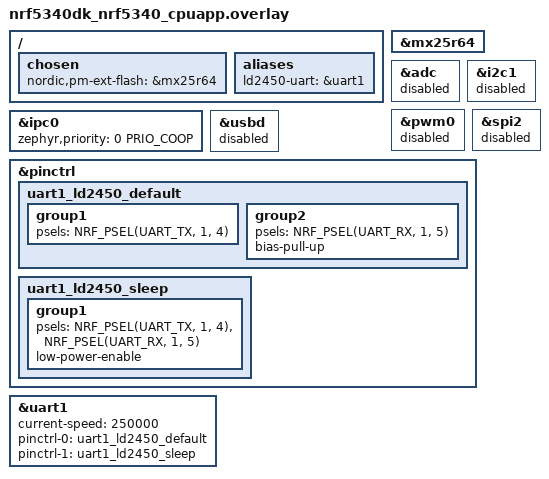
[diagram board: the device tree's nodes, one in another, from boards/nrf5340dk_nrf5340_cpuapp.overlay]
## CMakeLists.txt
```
#
# Copyright (c) 2025 Nordic Semiconductor ASA
#
# SPDX-License-Identifier: LicenseRef-Nordic-5-Clause
#

cmake_minimum_required(VERSION 3.20.0)

find_package(Zephyr HINTS $ENV{ZEPHYR_BASE})

project(matter-jamjari-occupancy)

# Enable GNU STD support.
include(${ZEPHYR_CONNECTEDHOMEIP_MODULE_DIR}/config/nrfconnect/app/enable-gnu-std.cmake)

# NORDIC SDK APP START

# Include all source files that are located in the Matter common directory.
include(${ZEPHYR_NRF_MODULE_DIR}/samples/matter/common/cmake/source_common.cmake)

# Include Data Model utils
include(${ZEPHYR_NRF_MODULE_DIR}/samples/matter/common/cmake/data_model.cmake)

include(${ZEPHYR_NRF_MODULE_DIR}/samples/matter/common/cmake/zap_helpers.cmake)
ncs_get_zap_parent_dir(ZAP_PARENT_DIR)

target_include_directories(app PRIVATE
  src
  ${ZAP_PARENT_DIR}
)

target_sources(app PRIVATE
  src/app_task.cpp
  src/bed_rules.cpp
  src/main.cpp
  src/ld2450.cpp
  src/ld2450_parser.cpp
  src/tracker.cpp
  src/zcl_callbacks.cpp
)
target_sources_ifdef(CONFIG_JAMJARI_DIRECT_UPLOAD app PRIVATE src/direct_upload.cpp)
# 재생 빌드: 재생 프레임(장면 시각·60GHz) 동기화 + 보드 추정
target_sources_ifdef(CONFIG_JAMJARI_RADAR_REPLAY app PRIVATE src/replay_frames.cpp)
target_sources_ifdef(CONFIG_JAMJARI_FUSION app PRIVATE src/fusion.cpp)

# 0x0431 은 SDK 에 서버 코드가 없다(초안 클러스터) — 속성 저장소만 쓴다
ncs_configure_data_model(EXTERNAL_CLUSTERS AMBIENT_CONTEXT_SENSING_CLUSTER)
# NORDIC SDK APP END
```

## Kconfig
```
#
# Copyright (c) 2025 Nordic Semiconductor
#
# SPDX-License-Identifier: LicenseRef-Nordic-5-Clause
#
mainmenu "Matter nRF Connect Jamjari Occupancy Sensor"

# 잠자리는 USB 전원이라 잠들 필요가 없다. 9/30 SED+LIT(ICD) 설정으로는 SmartThings 등록 중
# Thread 네트워크에 붙지 못하고 fail-safe 로 취소됐다. 전구 예제(등록 성공)와 같은 FTD·ICD 끔으로 둔다.
choice OPENTHREAD_NORDIC_LIBRARY_CONFIGURATION
	default OPENTHREAD_NORDIC_LIBRARY_FTD
endchoice

choice OPENTHREAD_DEVICE_TYPE
	default OPENTHREAD_FTD
endchoice

config CHIP_ENABLE_ICD_SUPPORT
	default n

menu "Jamjari direct upload"

config JAMJARI_DIRECT_UPLOAD
	bool "Board uploads events to the web server itself (Thread -> NAT64 -> HTTPS)"
	default n
	select MBEDTLS_TLS_LIBRARY
	# OT defconfig 가 TLS·클라이언트 기본값을 n 으로 둔다(조이너 등이 없을 때) → 여기서 켠다
	select MBEDTLS_SSL_TLS_C
	select MBEDTLS_SSL_CLI_C
	select PSA_WANT_KEY_TYPE_RSA_PUBLIC_KEY
	select PSA_WANT_RSA_KEY_SIZE_4096
	select PSA_WANT_ALG_RSA_PKCS1V15_SIGN
	select PSA_WANT_ALG_RSA_PSS
	# 뿌리 인증서가 SHA-384 로 서명됨(GTS R1). R4·X2(Cloudflare 쪽)는 P-384 키
	select PSA_WANT_ALG_SHA_384
	select PSA_WANT_ECC_SECP_R1_384
	help
	  E 계획: 보드가 맥 없이 SmartThings Station 의 NAT64 를 거쳐 jamjari.vercel.app 에
	  HTTPS 로 직접 올린다. Vercel 인증서가 RSA(루트 4096비트)라 RSA 검증을 켠다.
	  맥 수집기와 동시에 켜지 않는다(같은 사건이 두 번 저장됨).

endmenu

menu "Jamjari radar"

comment "지켜볼 구역(mm). 레이더 정면이 +y, 레이더에서 봐서 좌우가 x. 경계 포함."
comment "구역 밖 점은 사람으로 치지 않는다 (약 4m 거리의 유령 점을 거르려는 것)."

config JAMJARI_ZONE_XMIN
	int "Zone x min (mm)"
	range -6000 6000
	default -1500

config JAMJARI_ZONE_XMAX
	int "Zone x max (mm)"
	range -6000 6000
	default 1500

config JAMJARI_ZONE_YMIN
	int "Zone y min (mm)"
	range 0 8000
	default 0

config JAMJARI_ZONE_YMAX
	int "Zone y max (mm)"
	range 0 8000
	default 3000

config JAMJARI_RADAR_SUMMARY_LOG
	bool "Log a radar summary once per second"
	default y
	help
	  1초에 한 번 받은 프레임 수, 버린 바이트, 원시 타깃 수, 구역 안 사람(이름·x·y),
	  점유 상태를 INF 로 찍는다. 5초 넘게 프레임이 없으면 WRN 을 찍는다(이 경고는 끄지 않는다).

config JAMJARI_FRAME_LOG
	bool "Log one line per radar frame (for recording)"
	depends on LOG
	default y
	help
	  레이더 프레임 한 장마다 한 줄을 찍는다. 맥의 레이더_지도.py --source nrf 가 읽어서
	  지도로 그리고 녹화한다. 형식:
	    F <ms> <슬롯1> <슬롯2> <슬롯3> <구역 안 트랙 수> <occ>
	  슬롯은 원시 타깃 x,y,speed(mm, mm/s) 또는 빈 슬롯이면 -. 구역·트래커 전 값이다.
	  끝의 두 숫자는 보드가 그 프레임을 처리한 뒤의 판단(트랙 수, Occupancy 0/1).
	  한 줄 약 70바이트 × 초당 12장 ≈ 115200bps 의 8% 정도.

config JAMJARI_RADAR_REPLAY
	bool "Demo: read LD2450 frames from the Mac over VCOM instead of the radar"
	default n
	help
	  시연용(10/3, 센서 입력은 전부 더미로 가기로 함). 레이더 선 대신 디버거 USB 의 두 번째
	  통로(uart30, VCOM0, 115200bps)에서 LD2450 과 같은 30바이트 프레임을 받는다.
	  맥의 dummy/보드재생.py 가 더미 장면을 이 통로로 흘려 넣는다. 판단 코드는 그대로다.
	  ./build.sh --replay 가 replay/ 의 overlay·conf 로 켠다. 레이더용 빌드에는 쓰지 않는다.

config JAMJARI_FUSION
	bool "Board-side fusion: seat states + pet spots from replayed radar + 60GHz"
	depends on JAMJARI_RADAR_REPLAY
	default y
	help
	  보드 추정(10/5 N, 설계-보드추정.md). 맥 dummy/보드재생.py --g60 이 장면 시각을 붙여 보낸
	  레이더·60GHz 좌우 프레임으로 칸 상태(사람·반려동물로 추정·구분 안 됨·비어 있음)와
	  반려동물 머문 자리(10분 이상·최대 3개)를 보드에서 계산해 웹으로 보낸다(seat·spot 사건).
	  60GHz 는 가상 센서다.

comment "침대 칸 규칙 (설계-레이더2차.md). 침대 좌표가 모두 0 이면 끔 → 예전 규칙(구역 안 사람 있으면 1)."
comment "좌표계는 구역과 같다. 침대 사각형은 구역 안에 있어야 한다."

config JAMJARI_BED_XMIN
	int "Bed x min (mm)"
	range -6000 6000
	default 0

config JAMJARI_BED_XMAX
	int "Bed x max (mm)"
	range -6000 6000
	default 0

config JAMJARI_BED_YMIN
	int "Bed y min (mm)"
	range 0 8000
	default 0

config JAMJARI_BED_YMAX
	int "Bed y max (mm)"
	range 0 8000
	default 0

config JAMJARI_BED_SPLIT_X
	int "Bed left/right split x (mm)"
	range -6000 6000
	default 0
	help
	  x 가 이 값보다 작으면 왼쪽 칸(L), 아니면 오른쪽 칸(R). 레이더에서 본 기준.

config JAMJARI_BED_EDGE_MM
	int "Bed edge band width (mm)"
	range 0 2000
	default 300
	help
	  침대 좌우 두 변과 발치(ymin, 레이더 쪽) 안쪽 띠. 머리맡(ymax)은 띠 없음.
	  그 칸에서 온 점이 이 띠에서 사라지면 자리 뜸으로 본다.

config JAMJARI_LEAVE_DELAY_MS
	int "Delay before Occupancy=0 (ms)"
	range 1000 600000
	default 10000
	help
	  두 칸 다 꺼진 뒤(예전 규칙: 구역 안 사람이 없어진 뒤) Occupancy=0 까지.

config JAMJARI_HOLD_MAX_MIN
	int "Max hold without any point in bed (min)"
	range 1 1440
	default 720
	help
	  안전장치. 침대 안 점이 이만큼 하나도 없으면 두 칸 다 끈다.

config JAMJARI_MOVE_GAP_MS
	int "Movement gap that splits events (ms)"
	range 100 60000
	default 1000

config JAMJARI_MOVE_MIN_MS
	int "Minimum movement length (ms)"
	range 0 60000
	default 2000

config JAMJARI_FOLLOW_MS
	int "Follow window for L>R / R>L (ms)"
	range 0 600000
	default 30000
	help
	  한 칸 움직임이 끝나고 이 시간 안에 다른 칸이 시작하면 뒤쪽 줄에 「이어서 움직임」(L>R).
	  30000 = Pankhurst & Horne 1994 부부 연구의 30초 칸. 60000 = Hoffman 2020 개–사람 1분.
	  사람끼리 시차를 직접 잰 연구는 못 찾음(설계-레이더2차.md §3).

config JAMJARI_EVENT_LOG
	bool "Log JJ1,EV event lines"
	depends on LOG
	default y
	help
	  사건 줄 JJ1,EV,<seq>,<kind>,<start_ms>,<end_ms>,<size>,<x>,<y>,<count>,<flags>,<side> 를 찍는다.

endmenu

menu "Jamjari virtual temperature"

comment "시연용 가상 온도(endpoint 3). 범위는 ZAP 의 Min/MaxMeasuredValue(-10~40도)."

config JAMJARI_TEMP_START_CENTI
	int "Start temperature (0.01 C)"
	range -1000 4000
	default 2500

config JAMJARI_TEMP_STEP_CENTI
	int "Button step (0.01 C)"
	range 1 1000
	default 100

endmenu

source "$(ZEPHYR_CONNECTEDHOMEIP_MODULE_DIR)/config/nrfconnect/chip-module/Kconfig.features"
source "$(ZEPHYR_CONNECTEDHOMEIP_MODULE_DIR)/config/nrfconnect/chip-module/Kconfig.defaults"
source "$(ZEPHYR_NRF_MODULE_DIR)/samples/matter/common/src/Kconfig"
source "Kconfig.zephyr"
```

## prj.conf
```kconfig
#
# Copyright (c) 2025 Nordic Semiconductor ASA
#
# SPDX-License-Identifier: LicenseRef-Nordic-5-Clause
#

# Enable CHIP
CONFIG_CHIP=y
CONFIG_CHIP_PROJECT_CONFIG="src/chip_project_config.h"
CONFIG_CHIP_DEVICE_PRODUCT_NAME="Jamjari Occupancy Sensor"

# Configure ZAP file name
CONFIG_NCS_SAMPLE_MATTER_ZAP_FILE_PATH="${APPLICATION_CONFIG_DIR}/src/default_zap/occupancy_sensor.zap"

# 32768 == 0x8000 (example Product ID added temporaly,
# as there is no assigned PID on the following list:
# https://github.com/project-chip/connectedhomeip/blob/482e6fd03196a6de45465a90003947ef4b86e0b1/docs/examples/discussion/PID_allocation_for_example_apps.md)
CONFIG_CHIP_DEVICE_PRODUCT_ID=32768
CONFIG_STD_CPP17=y

# Enable Matter pairing automatically on application start.
CONFIG_CHIP_ENABLE_PAIRING_AUTOSTART=y

# Enable Matter extended announcement and increase duration to 1 hour.
CONFIG_CHIP_BLE_EXT_ADVERTISING=y
CONFIG_CHIP_BLE_ADVERTISING_DURATION=60

# Add support for LEDs and buttons on Nordic development kits
CONFIG_DK_LIBRARY=y

# Bluetooth Low Energy configuration
CONFIG_BT_DEVICE_NAME="Jamjari"
CONFIG_BT_DEVICE_NAME_MAX=18

# Suspend devices when the CPU goes into sleep
CONFIG_PM_DEVICE=y

# Other settings
CONFIG_THREAD_NAME=y
CONFIG_MPU_STACK_GUARD=y
CONFIG_RESET_ON_FATAL_ERROR=n
CONFIG_CHIP_LIB_SHELL=y
# E(보드 직접 전송) 1단계: 바깥 길 확인용 ot 셸 명령 (netdata·ping·dns)
CONFIG_OPENTHREAD_SHELL=y
# E 2단계①: OpenThread 를 소스로 빌드(미리 만든 FTD 라이브러리엔 TCP 가 없음). 기능 세트는 FTD 그대로
CONFIG_OPENTHREAD_SOURCES=y
CONFIG_OPENTHREAD_TCP_ENABLE=y
# TCP 를 켜면 OT 가 자기 TLS(ECJPAKE, 우리는 안 씀)까지 켜서 빌드가 깨짐 → 끔. 인터넷 TLS 는 앱에서 mbedTLS 로 따로
CONFIG_OPENTHREAD_CUSTOM_PARAMETERS="OPENTHREAD_CONFIG_TLS_ENABLE=0"
# E 2단계③: 보드가 HTTPS 로 직접 올리기 (Vercel 직통 · RSA 인증서 · SNI 필수)
CONFIG_JAMJARI_DIRECT_UPLOAD=y
# ECDHE-RSA 암호 묶음은 nrf_security 에서 아직 옛 RSA 설정(비공개 식별자)을 거쳐야 켜진다
CONFIG_MBEDTLS_DECLARE_PRIVATE_IDENTIFIERS=y
CONFIG_MBEDTLS_RSA_C=y
CONFIG_MBEDTLS_PKCS1_V15=y
CONFIG_MBEDTLS_PKCS1_V21=y
CONFIG_MBEDTLS_MPI_MAX_SIZE=512
CONFIG_MBEDTLS_KEY_EXCHANGE_ECDHE_RSA_ENABLED=y
CONFIG_MBEDTLS_SSL_SERVER_NAME_INDICATION=y
CONFIG_MBEDTLS_SSL_SRV_C=n
CONFIG_MBEDTLS_SSL_IN_CONTENT_LEN=16384
CONFIG_MBEDTLS_SSL_OUT_CONTENT_LEN=2048
CONFIG_MBEDTLS_HEAP_SIZE=49152

# Reduce application size
CONFIG_USE_SEGGER_RTT=n

# Enable Factory Data feature
CONFIG_CHIP_FACTORY_DATA=y
CONFIG_CHIP_FACTORY_DATA_BUILD=y

# 잠자리: HLK-LD2450 레이더 (uart1, 인터럽트 방식 수신)
CONFIG_SERIAL=y
CONFIG_UART_INTERRUPT_DRIVEN=y
```

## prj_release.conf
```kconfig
#
# Copyright (c) 2025 Nordic Semiconductor ASA
#
# SPDX-License-Identifier: LicenseRef-Nordic-5-Clause
#

# Enable CHIP
CONFIG_CHIP=y
CONFIG_CHIP_PROJECT_CONFIG="src/chip_project_config.h"
CONFIG_CHIP_DEVICE_PRODUCT_NAME="Jamjari Occupancy Sensor"

# Configure ZAP file name
CONFIG_NCS_SAMPLE_MATTER_ZAP_FILE_PATH="${APPLICATION_CONFIG_DIR}/src/default_zap/occupancy_sensor.zap"

# 32768 == 0x8000 (example Product ID added temporaly,
# as there is no assigned PID on the following list:
# https://github.com/project-chip/connectedhomeip/blob/482e6fd03196a6de45465a90003947ef4b86e0b1/docs/examples/discussion/PID_allocation_for_example_apps.md)
CONFIG_CHIP_DEVICE_PRODUCT_ID=32768
CONFIG_STD_CPP17=y

# Enable Matter pairing automatically on application start.
CONFIG_CHIP_ENABLE_PAIRING_AUTOSTART=y

# Enable Matter extended announcement and increase duration to 1 hour.
CONFIG_CHIP_BLE_EXT_ADVERTISING=y
CONFIG_CHIP_BLE_ADVERTISING_DURATION=60

# Add support for LEDs and buttons on Nordic development kits
CONFIG_DK_LIBRARY=y

# Try to disable unused RAM blocks to reduce power consumption
CONFIG_RAM_POWER_DOWN_LIBRARY=y

# Bluetooth Low Energy configuration
CONFIG_BT_DEVICE_NAME="Jamjari"
CONFIG_BT_DEVICE_NAME_MAX=18

# Suspend devices when the CPU goes into sleep
CONFIG_PM_DEVICE=y

# Enable system reset on fatal error
CONFIG_RESET_ON_FATAL_ERROR=y

# Disable all debug features
CONFIG_USE_SEGGER_RTT=n
CONFIG_SHELL=n
CONFIG_OPENTHREAD_SHELL=n
CONFIG_CONSOLE=n
CONFIG_UART_CONSOLE=n
# 콘솔은 끄되 LD2450 용 uart1 은 필요하다
CONFIG_SERIAL=y
CONFIG_UART_INTERRUPT_DRIVEN=y
CONFIG_LOG=n
CONFIG_LOG_MODE_MINIMAL=n
CONFIG_ASSERT_VERBOSE=n
CONFIG_ASSERT_NO_FILE_INFO=y
CONFIG_PRINTK=n
CONFIG_PRINTK_SYNC=n
CONFIG_THREAD_NAME=n
CONFIG_BOOT_BANNER=n

# Enable Factory Data feature
CONFIG_CHIP_FACTORY_DATA=y
CONFIG_CHIP_FACTORY_DATA_BUILD=y

# Enable Watchdog
CONFIG_NCS_SAMPLE_MATTER_WATCHDOG=y

# Enable LTO to decrease the flash usage.
CONFIG_LTO=y
CONFIG_ISR_TABLES_LOCAL_DECLARATION=y
```

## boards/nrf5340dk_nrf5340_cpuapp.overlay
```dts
/*
 * Copyright (c) 2025 Nordic Semiconductor ASA
 *
 * SPDX-License-Identifier: LicenseRef-Nordic-5-Clause
 */

#include <samples/matter/nrf5340_cpuapp_partitions.dtsi>
#include <zephyr/dt-bindings/ipc_service/static_vrings.h>

/* Set IPC thread priority to the highest value to not collide with other threads. */
&ipc0 {
	zephyr,priority = <0 PRIO_COOP>;
};

/ {
	chosen {
		nordic,pm-ext-flash = &mx25r64;
	};
};

&mx25r64 {
	status = "okay";
};

/* Disable unused peripherals to reduce power consumption */
&adc {
	status = "disabled";
};

&i2c1 {
	status = "disabled";
};

&pwm0 {
	status = "disabled";
};

&spi2 {
	status = "disabled";
};

&usbd {
	status = "disabled";
};

/*
 * 잠자리: HLK-LD2450 레이더용 UART.
 * uart1 의 기본 핀(P1.00/P1.01)은 네트워크 코어 UART 로 넘겨지고(gpio_fwd)
 * DK 디버거 VCOM 에도 물려 있어서 쓰지 않는다. 비어 있는 Arduino D2/D3 로 옮긴다.
 *   TX  P1.04 (Arduino D2) -> LD2450 RX
 *   RX  P1.05 (Arduino D3) <- LD2450 TX
 * UARTE1 은 TWIM1(i2c1) 과 같은 주변장치를 공유한다. i2c1 은 위에서 disabled.
 * current-speed 는 드라이버가 허용하는 250000 으로 두고, 실제 256000 설정은
 * src/ld2450.cpp 에서 BAUDRATE 레지스터에 직접 쓴다.
 */
/ {
	aliases {
		ld2450-uart = &uart1;
	};
};

&pinctrl {
	uart1_ld2450_default: uart1_ld2450_default {
		group1 {
			psels = <NRF_PSEL(UART_TX, 1, 4)>;
		};
		group2 {
			psels = <NRF_PSEL(UART_RX, 1, 5)>;
			bias-pull-up;
		};
	};

	uart1_ld2450_sleep: uart1_ld2450_sleep {
		group1 {
			psels = <NRF_PSEL(UART_TX, 1, 4)>,
				<NRF_PSEL(UART_RX, 1, 5)>;
			low-power-enable;
		};
	};
};

&uart1 {
	status = "okay";
	current-speed = <250000>;
	pinctrl-0 = <&uart1_ld2450_default>;
	pinctrl-1 = <&uart1_ld2450_sleep>;
	pinctrl-names = "default", "sleep";
};
```

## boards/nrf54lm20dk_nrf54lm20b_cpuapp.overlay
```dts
/*
 * Copyright (c) 2026 Nordic Semiconductor ASA
 *
 * SPDX-License-Identifier: LicenseRef-Nordic-5-Clause
 */

#include <samples/matter/nrf54lm20_cpuapp_partitions.dtsi>

/ {
	aliases {
		/* Use watchdog wdt31 as the application watchdog */
		watchdog0 = &wdt31;
	};

	chosen {
		nordic,pm-ext-flash = &mx25r64;
	};
};

&mx25r64 {
	status = "okay";
};

&wdt31 {
	status = "okay";
};

/*
 * 잠자리: HLK-LD2450 레이더용 UART (nRF54LM20 DK).
 * uart20 은 콘솔(디버거 VCOM)이라 쓰지 않고, 비어 있는 uart21 을 쓴다.
 * uart21 은 16MHz 주변장치 도메인이라 src/ld2450.cpp 의 256000 BAUDRATE 레지스터 값
 * (16MHz 기준 공식)이 그대로 맞다. 핀은 확장 헤더의 P1 포트에서 고른다
 * (주변장치 도메인 UARTE 는 P1 핀을 쓴다).
 *   TX  P1.04 -> LD2450 RX
 *   RX  P1.05 <- LD2450 TX
 * 🔴 DK 의 VDD(GPIO 전압) 기본값이 1.8V 일 수 있다. 레이더 TX 는 3.3V 라서
 *    Board Configurator 로 VDD 를 3.3V 로 올린 뒤에 선을 꽂는다.
 */
/ {
	aliases {
		ld2450-uart = &uart21;
	};
};

&pinctrl {
	uart21_ld2450_default: uart21_ld2450_default {
		group1 {
			psels = <NRF_PSEL(UART_TX, 1, 4)>;
		};
		group2 {
			psels = <NRF_PSEL(UART_RX, 1, 5)>;
			bias-pull-up;
		};
	};

	uart21_ld2450_sleep: uart21_ld2450_sleep {
		group1 {
			psels = <NRF_PSEL(UART_TX, 1, 4)>,
				<NRF_PSEL(UART_RX, 1, 5)>;
			low-power-enable;
		};
	};
};

&uart21 {
	status = "okay";
	current-speed = <250000>;
	pinctrl-0 = <&uart21_ld2450_default>;
	pinctrl-1 = <&uart21_ld2450_sleep>;
	pinctrl-names = "default", "sleep";
};
```

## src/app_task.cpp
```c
/*
 * Copyright (c) 2025 Nordic Semiconductor ASA
 *
 * SPDX-License-Identifier: LicenseRef-Nordic-5-Clause
 */

#include "app_task.h"
#include "bed_rules.h"
#ifdef CONFIG_JAMJARI_DIRECT_UPLOAD
#include "direct_upload.h"
#endif
#ifdef CONFIG_JAMJARI_FUSION
#include "fusion.h"
#include "ld2450_parser.h"
#include "replay_frames.h"
#endif
#include "ld2450.h"
#include "tracker.h"

#include "app/matter_init.h"
#include "app/task_executor.h"
#include "board/board.h"
#include "clusters/identify.h"

#include "lib/core/CHIPError.h"
#include <app-common/zap-generated/attribute-type.h>
#include <app-common/zap-generated/attributes/Accessors.h>
#include <app/clusters/occupancy-sensor-server/occupancy-sensor-server.h>
#include <app/util/attribute-table.h>

#include <dk_buttons_and_leds.h>
#include <zephyr/logging/log.h>
#include <zephyr/shell/shell.h>

#include <cstdio>
#include <cstdlib>
#include <cstring>

LOG_MODULE_DECLARE(app, CONFIG_CHIP_APP_LOG_LEVEL);

using namespace ::chip;
using namespace ::chip::app;
using namespace ::chip::DeviceLayer;

namespace
{
constexpr chip::EndpointId kOccupancySensorEndpointId = 1;
/* 0x0431 Ambient Context Sensing (Matter 다음 규격 초안, ZAP 정의는 src/default_zap/zcl/) */
constexpr chip::ClusterId kAmbientContextSensingClusterId = 0x0431;
constexpr chip::AttributeId kHumanActivityDetectedAttributeId = 0x0000;
/*
 * 시연용 가상 조도 (Light Sensor). 5 lux 고정(ZAP 기본값 6991 = 10000*log10(5)+1).
 * SmartThings Matter Sensor 드라이버에 「동작+온도」 모양이 없고 「동작+조도+온도」는 있어서 넣었다.
 * 예전 ep2 「감지 멈춤」 On/Off 스위치는 SmartThings 가 기기 전체를 플러그로 잡아 동작 감지를 가려서 뺐다 → BTN2 만 남음.
 */
constexpr chip::EndpointId kLightSensorEndpointId = 2;
/* 시연용 가상 온도 (Temperature Sensor). 값은 버튼·셸(temp)로만 바뀐다. */
constexpr chip::EndpointId kTemperatureSensorEndpointId = 3;

atomic_t sOccupied = ATOMIC_INIT(0);
/* 멈춤 요청(1=멈춤). Matter 스레드가 쓰고, 리더 스레드가 ApplyPauseState 로 반영한다. */
atomic_t sPaused = ATOMIC_INIT(0);

/* Identify 가 끝나면 LED2 를 끄지 말고 지금 Occupancy 로 되돌린다 */
void RestoreOccupancyLed()
{
	Nrf::PostTask([] { Nrf::GetBoard().GetLED(Nrf::DeviceLeds::LED2).Set(atomic_get(&sOccupied) != 0); });
}

Nrf::Matter::IdentifyCluster sIdentifyCluster(kOccupancySensorEndpointId, true, RestoreOccupancyLed);
Nrf::Matter::IdentifyCluster sLightIdentifyCluster(kLightSensorEndpointId, true, RestoreOccupancyLed);
Nrf::Matter::IdentifyCluster sTempIdentifyCluster(kTemperatureSensorEndpointId, true, RestoreOccupancyLed);

/* FeatureMap = Radar. 이 클러스터의 FeatureMap/ClusterRevision 은 이 인스턴스가 응답한다. */
Clusters::OccupancySensing::Instance
	sOccupancyInstance(BitMask<Clusters::OccupancySensing::Feature>(Clusters::OccupancySensing::Feature::kRadar));

/* 지켜볼 구역(mm). Kconfig CONFIG_JAMJARI_ZONE_* 로 바꾼다(README 「구역 조정」). */
constexpr Tracker::Zone kZone = { CONFIG_JAMJARI_ZONE_XMIN, CONFIG_JAMJARI_ZONE_XMAX, CONFIG_JAMJARI_ZONE_YMIN,
				  CONFIG_JAMJARI_ZONE_YMAX };
constexpr int64_t kRadarSilentMs = 5000;

/* 침대 칸 규칙(bed_rules.h). 침대 좌표가 모두 0 이면 예전 규칙. Kconfig CONFIG_JAMJARI_BED_* 등 */
constexpr BedRules::Config kBedConfig = {
	{ CONFIG_JAMJARI_BED_XMIN, CONFIG_JAMJARI_BED_XMAX, CONFIG_JAMJARI_BED_YMIN, CONFIG_JAMJARI_BED_YMAX,
	  CONFIG_JAMJARI_BED_SPLIT_X, CONFIG_JAMJARI_BED_EDGE_MM },
	CONFIG_JAMJARI_LEAVE_DELAY_MS,
	static_cast<int64_t>(CONFIG_JAMJARI_HOLD_MAX_MIN) * 60 * 1000,
	CONFIG_JAMJARI_MOVE_GAP_MS,
	CONFIG_JAMJARI_MOVE_MIN_MS,
	CONFIG_JAMJARI_FOLLOW_MS,
};

/* 침대 좌표 오설정은 빌드에서 막는다(미설정 = 모두 0 이면 검사 안 함) */
constexpr bool kBedSet = CONFIG_JAMJARI_BED_XMIN != 0 || CONFIG_JAMJARI_BED_XMAX != 0 ||
			 CONFIG_JAMJARI_BED_YMIN != 0 || CONFIG_JAMJARI_BED_YMAX != 0;
static_assert(!kBedSet || (CONFIG_JAMJARI_BED_XMIN < CONFIG_JAMJARI_BED_XMAX &&
			   CONFIG_JAMJARI_BED_YMIN < CONFIG_JAMJARI_BED_YMAX),
	      "침대 좌표: XMIN<XMAX, YMIN<YMAX 이어야 한다 (네 값을 다 넣었나?)");
static_assert(!kBedSet || (CONFIG_JAMJARI_BED_XMIN <= CONFIG_JAMJARI_BED_SPLIT_X &&
			   CONFIG_JAMJARI_BED_SPLIT_X <= CONFIG_JAMJARI_BED_XMAX),
	      "침대 좌표: SPLIT_X 는 XMIN..XMAX 안이어야 한다");
static_assert(!kBedSet || (2 * CONFIG_JAMJARI_BED_EDGE_MM < CONFIG_JAMJARI_BED_XMAX - CONFIG_JAMJARI_BED_XMIN &&
			   CONFIG_JAMJARI_BED_EDGE_MM < CONFIG_JAMJARI_BED_YMAX - CONFIG_JAMJARI_BED_YMIN),
	      "침대 좌표: 가장자리 띠가 침대보다 넓다 (EDGE_MM 줄이기)");
static_assert(!kBedSet || (CONFIG_JAMJARI_ZONE_XMIN <= CONFIG_JAMJARI_BED_XMIN &&
			   CONFIG_JAMJARI_BED_XMAX <= CONFIG_JAMJARI_ZONE_XMAX &&
			   CONFIG_JAMJARI_ZONE_YMIN <= CONFIG_JAMJARI_BED_YMIN &&
			   CONFIG_JAMJARI_BED_YMAX <= CONFIG_JAMJARI_ZONE_YMAX),
	      "침대 좌표: 침대는 구역(JAMJARI_ZONE_*) 안에 있어야 한다 (밖은 트래커가 버린다)");

/* 아래 셋은 LD2450 리더 스레드에서만 만진다(프레임 핸들러와 1초 틱이 같은 스레드) */
Tracker::State sTracker;
BedRules::State sBed;
uint8_t sLastRawCount;
int64_t sLastSilentWarnMs;
bool sAppliedPaused; /* 리더 스레드가 마지막으로 반영한 멈춤 상태 */

void ReportOccupancy(bool occupied)
{
	/* 상태가 바뀔 때만 Matter 스레드에 넘긴다 */
	if (atomic_set(&sOccupied, occupied ? 1 : 0) == (occupied ? 1 : 0)) {
		return;
	}
	LOG_INF("Occupancy -> %d", occupied);
	/*
	 * 레이더 리더 스레드와 시스템 워크큐(SetSensing — BTN2 콜백) 둘 다 부른다. 두 스레드가 거의 같이 부르면 일이 두 개
	 * 쌓이는데, 일은 넘길 때 값이 아니라 실행할 때 sOccupied 를 읽는다 — 마지막 일이 늘 최신 값을 쓰므로
	 * 속성과 LED2 가 sOccupied 와 어긋난 채 남지 않는다. LED 는 앱 스레드에서 바꾼다.
	 */
	DeviceLayer::PlatformMgr().ScheduleWork(
		[](intptr_t) {
			bool now = atomic_get(&sOccupied) != 0;
			Nrf::PostTask([now] { Nrf::GetBoard().GetLED(Nrf::DeviceLeds::LED2).Set(now); });
			BitMask<Clusters::OccupancySensing::OccupancyBitmap> value;
			if (now) {
				value.Set(Clusters::OccupancySensing::OccupancyBitmap::kOccupied);
			}
			Protocols::InteractionModel::Status status =
				Clusters::OccupancySensing::Attributes::Occupancy::Set(kOccupancySensorEndpointId,
										       value);
			if (status != Protocols::InteractionModel::Status::Success) {
				LOG_ERR("Updating occupancy failed %x", to_underlying(status));
			}
			/*
			 * 0x0431 Ambient Context Sensing(초안) HumanActivityDetected 도 같은 값으로. SDK 에 이 클러스터의
			 * Accessors 가 없어서 속성 저장소에 바로 쓴다(Matter 스레드라 잠금 안). HumanActivityType 은 Other(0) 고정.
			 */
			uint8_t detected = now ? 1 : 0;
			status = emberAfWriteAttribute(kOccupancySensorEndpointId, kAmbientContextSensingClusterId,
						       kHumanActivityDetectedAttributeId, &detected,
						       ZCL_BOOLEAN_ATTRIBUTE_TYPE);
			if (status != Protocols::InteractionModel::Status::Success) {
				LOG_ERR("Updating 0x0431 HumanActivityDetected failed %x", to_underlying(status));
			}
		},
		0);
}

/*
 * 리더 스레드에서 프레임·틱마다 맨 먼저 부른다. 반환값 = 지금 멈춤인가.
 * 멈춤/재개가 바뀌는 순간 트래커와 침대 칸 상태를 새로 시작한다 — 열려 있던 사건(움직임 묶음·away)은
 * 버린다. 사건 번호(seq)만 이어 간다(맥 쪽이 번호로 줄을 맞춘다).
 */
bool ApplyPauseState()
{
	bool paused = atomic_get(&sPaused) != 0;
	if (paused == sAppliedPaused) {
		return paused;
	}
	sAppliedPaused = paused;
	uint32_t seq = sBed.seq;
	sTracker = {};
	sBed = {};
	sBed.seq = seq;
	if (paused) {
		/* 멈춤 중엔 비어 있음으로 둔다(SetSensing 도 내리지만, 그 사이 프레임이 올렸을 수 있다) */
		ReportOccupancy(false);
	}
	return paused;
}

/* 사건 줄 출력 (Kconfig JAMJARI_EVENT_LOG). 맥은 JJ1, 이후만 읽는다.
 * 직접 전송(JAMJARI_DIRECT_UPLOAD)이면 같은 사건을 보낼 줄에도 넣는다. */
void LogEvents(const BedRules::EventBuf &out)
{
#ifdef CONFIG_JAMJARI_DIRECT_UPLOAD
	for (size_t i = 0; i < out.n; i++) {
		DirectUpload::QueueEvent(out.ev[i]);
	}
#endif
#ifdef CONFIG_JAMJARI_EVENT_LOG
	for (size_t i = 0; i < out.n; i++) {
		char line[96];
		BedRules::FormatEvent(out.ev[i], line, sizeof(line));
		LOG_INF("%s", line);
	}
	if (out.overflow) {
		LOG_WRN("사건 %u개 못 냄 (EventBuf 가득)", static_cast<unsigned>(out.overflow));
	}
#else
	ARG_UNUSED(out);
#endif
}

/* 프레임 한 줄 출력: F <ms> <슬롯×3> <트랙 수> <occ> (Kconfig JAMJARI_FRAME_LOG, 맥의 레이더_지도.py --source nrf 가 읽는다) */
void LogFrame(const Ld2450::Target (&targets)[Ld2450::kTargetSlots])
{
#ifdef CONFIG_JAMJARI_FRAME_LOG
	/* 슬롯 하나 최대 " -32767,-32767,-327670" 22자 */
	char slots[Ld2450::kTargetSlots * 24] = "";
	size_t len = 0;
	for (size_t i = 0; i < Ld2450::kTargetSlots; i++) {
		const Ld2450::Target &t = targets[i];
		int n = t.present ? snprintf(slots + len, sizeof(slots) - len, " %d,%d,%d", t.x, t.y,
					     static_cast<int>(t.speed))
				  : snprintf(slots + len, sizeof(slots) - len, " -");
		if (n < 0 || static_cast<size_t>(n) >= sizeof(slots) - len) {
			break;
		}
		len += static_cast<size_t>(n);
	}
	LOG_INF("F %u%s %u %d", static_cast<unsigned>(k_uptime_get_32()), slots,
		static_cast<unsigned>(sTracker.count), static_cast<int>(atomic_get(&sOccupied)));
#else
	ARG_UNUSED(targets);
#endif
}

/*
 * LD2450 리더 스레드에서 프레임마다 불린다.
 * 구역 필터·트래커 → 침대 칸 규칙(bed_rules) 순서. 원시 타깃이 아니라 트래커 결과로 판정한다 —
 * 구역 밖 유령 점이 Occupancy 를 붙잡지 않게. 침대 좌표 미설정이면 예전 규칙(구역 안 사람 1명 이상 → 1,
 * 마지막으로 있던 때부터 10초 → 0). (호스트 테스트: test/run_tracker.cpp 는 예전 규칙을 occupancy.h 로 본다)
 */
void OnRadarFrame(const Ld2450::Target (&targets)[Ld2450::kTargetSlots], uint8_t liveCount)
{
	sLastRawCount = liveCount;
	if (ApplyPauseState()) {
		return;
	}
	int64_t nowMs = k_uptime_get();
	Tracker::Update(sTracker, targets, kZone, nowMs);
	BedRules::EventBuf out;
	bool occupied = BedRules::Update(sBed, kBedConfig, sTracker, nowMs, out);
	/* 판단 도중 멈춤이 들어왔으면 결과를 버린다(JJ1,PAUSE,1 뒤에 occ 1·JJ1,EV 가 나가지 않게) */
	if (atomic_get(&sPaused)) {
		return;
	}
	ReportOccupancy(occupied);
	LogEvents(out);
	LogFrame(targets);
}

#ifdef CONFIG_JAMJARI_FUSION
/*
 * 보드 추정(fusion, 설계-보드추정.md). 맥이 장면 시각을 붙여 보낸 프레임으로 칸 상태·머문 자리를 계산한다.
 * 리더 스레드에서만 불린다(sFusion 은 이 스레드 전용). 결과는 로그 한 줄 + 웹 전송 줄(seat·spot).
 *   JJ1,SEAT,<장면 초>,<L|R>,<0 비어 있음|1 사람|2 반려동물로 추정|3 구분 안 됨>,<단서 0~3: A=1 B=2>
 *   JJ1,SPOT,<순위>,<from 초>,<to 초>,<x>,<y>,<머문 초>
 */
Fusion::Engine sFusion;
Fusion::SideOut sSeatPrev[2];
bool sSeatSent;
uint32_t sFusionSeq; /* 웹 src_id 가 bed_rules 사건과 안 겹치게 위 비트를 켠 번호를 쓴다 */
int32_t sSec0 = -1, sSecLast; /* 장면 초 ↔ 보드 시계: 첫 초와 마지막 초에 받은 보드 시각으로 선형 대응 */
int64_t sUp0, sUpLast;

void FusionReset()
{
	Fusion::Init(sFusion);
	sSeatSent = false;
	sSec0 = -1;
}

int64_t SceneToUptime(int32_t sec)
{
	if (sSec0 < 0 || sSecLast <= sSec0) {
		return sUp0;
	}
	return sUp0 + (static_cast<int64_t>(sec) - sSec0) * (sUpLast - sUp0) / (sSecLast - sSec0);
}

void QueueFusionEvent(BedRules::Kind kind, int64_t startMs, int64_t endMs, uint8_t size, int32_t x, int32_t y,
		      uint8_t count)
{
#ifdef CONFIG_JAMJARI_DIRECT_UPLOAD
	BedRules::Event ev = {};
	ev.seq = 0x80000000u | ++sFusionSeq;
	ev.kind = kind;
	ev.startMs = startMs;
	ev.endMs = endMs;
	ev.size = size;
	ev.x = x;
	ev.y = y;
	ev.count = count;
	DirectUpload::QueueEvent(ev);
#endif
}

Fusion::G60 G60Side(const uint8_t *p)
{
	return { p[0], static_cast<int16_t>(p[1] == 0xFF ? -1 : p[1]), static_cast<int16_t>(p[2] == 0xFF ? -1 : p[2]), p[3] };
}

void OnReplayFrame(const uint8_t *frame)
{
	using ReplayFrames::Type;
	Type type = static_cast<Type>(frame[2]);
	if (type == Type::kStart) {
		LOG_INF("fusion: 재생 시작 → 새로 시작");
		FusionReset();
		return;
	}
	/* 감지 멈춤 중엔 추정도 멈춘다. 장면 끝은 리셋만 한다(멈춘 동안의 결과는 안 낸다) */
	if (atomic_get(&sPaused)) {
		if (type == Type::kEnd) {
			LOG_INF("fusion: 감지 멈춤 중 장면 끝 → 머문 자리 안 내고 새로 시작");
			FusionReset();
		}
		return;
	}
	switch (type) {
	case Type::kRadar: {
		Ld2450::Target targets[Ld2450::kTargetSlots];
		Ld2450::ParseFrame(frame + 4, targets);
		Fusion::Point pts[Ld2450::kTargetSlots];
		size_t n = 0;
		for (const auto &t : targets) {
			if (t.present) {
				pts[n++] = { t.x, t.y };
			}
		}
		Fusion::Radar(sFusion, ReplayFrames::U32(frame + 4) / 1000.0, pts, n);
		break;
	}
	case Type::kG60: {
		int32_t sec = static_cast<int32_t>(ReplayFrames::U32(frame + 4));
		/* 장면 초는 1씩 이어진다. 안 이어지면(시작 프레임을 놓친 다른 재생) 새로 시작 */
		if (sSec0 >= 0 && sec != sFusion.judged) {
			LOG_INF("fusion: 장면 초가 안 이어짐(%d초, 기대 %d초) → 새로 시작", sec, sFusion.judged);
			FusionReset();
		}
		int64_t now = k_uptime_get();
		if (sSec0 < 0) {
			sSec0 = sec;
			sUp0 = now;
		}
		sSecLast = sec;
		sUpLast = now;
		Fusion::SecondOut o = Fusion::Judge(sFusion, sec, G60Side(frame + 8), G60Side(frame + 12));
		for (int side = 0; side < 2; side++) {
			const Fusion::SideOut &s = o.side[side];
			if (sSeatSent && s.state == sSeatPrev[side].state && s.clues == sSeatPrev[side].clues) {
				continue;
			}
			sSeatPrev[side] = s;
			LOG_INF("JJ1,SEAT,%d,%c,%u,%u", sec, side ? 'R' : 'L', static_cast<unsigned>(s.state),
				static_cast<unsigned>(s.clues));
			/* 칸은 x 부호로(L 음수·R 양수, 칸 가운데), 상태는 size, 단서는 count */
			QueueFusionEvent(BedRules::Kind::kSeat, now, now, static_cast<uint8_t>(s.state), side ? 400 : -400,
					 1300, s.clues);
		}
		sSeatSent = true;
		break;
	}
	case Type::kEnd: {
		Fusion::Spot spots[Fusion::kMaxSpots];
		size_t n = Fusion::End(sFusion, spots);
		LOG_INF("fusion: 장면 끝 %d초, 머문 자리 %u개 (넘침 트랙 %u/%u 자리 %u)", sFusion.judged,
			static_cast<unsigned>(n), static_cast<unsigned>(sFusion.m.overflow),
			static_cast<unsigned>(sFusion.n.overflow), static_cast<unsigned>(sFusion.s.overflow));
		for (size_t i = 0; i < n; i++) {
			const Fusion::Spot &sp = spots[i];
			LOG_INF("JJ1,SPOT,%u,%d,%d,%d,%d,%d", static_cast<unsigned>(i + 1), sp.from, sp.to, sp.x, sp.y,
				sp.still);
			int32_t minutes = sp.still / 60;
			QueueFusionEvent(BedRules::Kind::kSpot, SceneToUptime(sp.from), SceneToUptime(sp.to),
					 static_cast<uint8_t>(i + 1), sp.x, sp.y, static_cast<uint8_t>(minutes > 255 ? 255 : minutes));
		}
		FusionReset();
		break;
	}
	default:
		break;
	}
}
#endif

/* LD2450 리더 스레드에서 1초마다 불린다: 레이더 상태 요약 + 신호 끊김 경고 */
void OnRadarTick(const Ld2450::Stats &stats, int64_t nowMs)
{
	bool paused = ApplyPauseState();
	if (!paused) {
		/* 프레임이 끊겨도 시간으로 내리는 판단(occ 0·움직임 닫기)은 여기서 */
		BedRules::EventBuf out;
		bool occupied = BedRules::Tick(sBed, kBedConfig, nowMs, out);
		/* 판단 도중 멈춤이 들어왔으면 결과를 버린다(OnRadarFrame 과 같은 이유) */
		if (!atomic_get(&sPaused)) {
			ReportOccupancy(occupied);
			LogEvents(out);
		}
	}
#ifdef CONFIG_JAMJARI_DIRECT_UPLOAD
	/* 레이더 상태 숫자는 멈춤 중에도 갱신(보낼 묶음의 상태 칸) */
	DirectUpload::NoteRadarStats(stats);
#endif

	/* 레이더 끊김 경고는 멈춤 중에도 낸다 */
	int64_t silentMs = nowMs - (stats.lastFrameMs < 0 ? 0 : stats.lastFrameMs);
	if (silentMs > kRadarSilentMs && nowMs - sLastSilentWarnMs >= kRadarSilentMs) {
		sLastSilentWarnMs = nowMs;
		LOG_WRN("레이더 신호 없음 — 배선/5V 확인 (%lld초째 프레임 없음, 누적 %u프레임)",
			static_cast<long long>(silentMs / 1000), stats.frames);
	}

#ifdef CONFIG_JAMJARI_RADAR_SUMMARY_LOG
	static Ld2450::Stats sPrev = { 0, 0, 0, -1 };
	if (paused) {
		sPrev = stats; /* 재개 첫 줄의 fps 가 멈춤 동안 누적값이 되지 않게 */
		return;
	}
	char people[Tracker::kMaxTracks * 24] = "";
	size_t len = 0;
	for (size_t i = 0; i < sTracker.count && len < sizeof(people); i++) {
		const Tracker::Track &t = sTracker.tracks[i];
		char name[Tracker::kNameBufLen];
		Tracker::FormatName(t.nameIndex, name);
		/* 이번 프레임에 안 잡혀 이름만 살려 둔 트랙은 뒤에 ? */
		int n = snprintf(people + len, sizeof(people) - len, " %s%s(%d,%d)", name, t.seen ? "" : "?",
				 t.x, t.y);
		if (n < 0) {
			break;
		}
		len += static_cast<size_t>(n);
	}
	LOG_INF("radar %u fps, drop %uB, qdrop %u, raw %u, zone %u:%s, occ %d", stats.frames - sPrev.frames,
		stats.droppedBytes - sPrev.droppedBytes, stats.queueDrops - sPrev.queueDrops, sLastRawCount,
		static_cast<unsigned>(sTracker.count), sTracker.count ? people : " -",
		static_cast<int>(atomic_get(&sOccupied)));
	sPrev = stats;
#endif
}

#ifdef CONFIG_CHIP_ICD_UAT_SUPPORT
#define UAT_BUTTON_MASK DK_BTN3_MSK
#endif
/* BTN1 은 보드 공용 기능 버튼. BTN2 = 감지 멈춤 뒤집기(보드에서만. 저장 안 함 — 재부팅하면 감지) */
#define PAUSE_BUTTON_MASK DK_BTN2_MSK
/* BTN3 = 가상 온도 올리기, BTN4 = 내리기. BTN3 은 ICD UAT 가 켜지면 겹친다(지금은 ICD 끔). */
#ifdef CONFIG_CHIP_ICD_UAT_SUPPORT
#error "BTN3 을 ICD UAT 와 가상 온도 올리기가 같이 쓴다 — 버튼을 다시 나눌 것"
#endif
#define TEMP_UP_BUTTON_MASK DK_BTN3_MSK
#define TEMP_DOWN_BUTTON_MASK DK_BTN4_MSK

/* "28", "27.5", "-3.25" 를 0.01 C 단위로 바꾼다. 소수 셋째 자리부터는 버린다. */
bool ParseCentiDegrees(const char *text, int32_t &out)
{
	const char *p = text;
	bool negative = false;
	if (*p == '-' || *p == '+') {
		negative = (*p == '-');
		p++;
	}
	if (*p < '0' || *p > '9') {
		return false;
	}

	char *end;
	long whole = strtol(p, &end, 10);
	int32_t frac = 0;
	if (*end == '.') {
		end++;
		int digits = 0;
		while (*end >= '0' && *end <= '9') {
			if (digits < 2) {
				frac = frac * 10 + (*end - '0');
			}
			digits++;
			end++;
		}
		if (digits == 0) {
			return false;
		}
		if (digits == 1) {
			frac *= 10;
		}
	}
	if (*end != '\0' || whole > 1000) {
		return false;
	}

	int32_t value = static_cast<int32_t>(whole) * 100 + frac;
	out = negative ? -value : value;
	return true;
}

void PrintTemperature(const struct shell *sh, int16_t centi)
{
	int32_t absolute = centi < 0 ? -centi : centi;
	shell_print(sh, "temp %s%d.%02d C (virtual)", centi < 0 ? "-" : "", absolute / 100, absolute % 100);
}

int CmdTemp(const struct shell *sh, size_t argc, char **argv)
{
	AppTask &app = AppTask::Instance();

	if (argc == 1) {
		PrintTemperature(sh, app.GetCurrentTemperature());
		return 0;
	}

	if (strcmp(argv[1], "up") == 0) {
		app.StepTemperature(CONFIG_JAMJARI_TEMP_STEP_CENTI);
	} else if (strcmp(argv[1], "down") == 0) {
		app.StepTemperature(-CONFIG_JAMJARI_TEMP_STEP_CENTI);
	} else {
		int32_t centi;
		if (!ParseCentiDegrees(argv[1], centi)) {
			shell_error(sh, "usage: temp [<C> | up | down]   e.g. temp 28, temp 27.5");
			return -EINVAL;
		}
		if (centi < app.GetMinTemperature() || centi > app.GetMaxTemperature()) {
			shell_error(sh, "out of range (%d..%d, 0.01 C)", app.GetMinTemperature(), app.GetMaxTemperature());
			return -EINVAL;
		}
		app.SetTemperature(static_cast<int16_t>(centi));
	}

	shell_print(sh, "ok");
	return 0;
}

SHELL_CMD_ARG_REGISTER(temp, NULL, "Virtual temperature: temp [<C> | up | down]", CmdTemp, 1, 1);
} /* namespace */

void AppTask::SetSensing(bool on)
{
	/* 부팅 때(Init) 첫 호출은 바뀌지 않아도 한 줄 낸다 */
	static bool sLogged;
	bool paused = !on;
	bool was = atomic_set(&sPaused, paused ? 1 : 0) != 0;
	if (sLogged && was == paused) {
		return;
	}
	sLogged = true;
	LOG_INF("JJ1,PAUSE,%d,%u", paused ? 1 : 0, static_cast<unsigned>(k_uptime_get_32()));
	Nrf::PostTask([paused] { Nrf::GetBoard().GetLED(Nrf::DeviceLeds::LED3).Set(paused); });
	if (paused) {
		/* 레이더 스레드가 안 돌아도 1초 안에 비어 있음이 되게 바로 내린다(같은 값이면 아무것도 안 함) */
		ReportOccupancy(false);
	}
}

void AppTask::ButtonEventHandler(Nrf::ButtonState state, Nrf::ButtonMask hasChanged)
{
#ifdef CONFIG_CHIP_ICD_UAT_SUPPORT
	if ((UAT_BUTTON_MASK & state & hasChanged)) {
		LOG_INF("ICD UserActiveMode has been triggered.");
		Server::GetInstance().GetICDManager().OnNetworkActivity();
	}
#endif
	if (PAUSE_BUTTON_MASK & state & hasChanged) {
		SetSensing(atomic_get(&sPaused) != 0);
	}
	/* 가상 온도: 누를 때만 반응한다(뗄 때는 무시). */
	if (TEMP_UP_BUTTON_MASK & state & hasChanged) {
		Instance().StepTemperature(CONFIG_JAMJARI_TEMP_STEP_CENTI);
	}
	if (TEMP_DOWN_BUTTON_MASK & state & hasChanged) {
		Instance().StepTemperature(-CONFIG_JAMJARI_TEMP_STEP_CENTI);
	}
}

void AppTask::SetTemperature(int16_t centi)
{
	PlatformMgr().ScheduleWork([](intptr_t arg) { Instance().ApplyTemperature(static_cast<int32_t>(arg)); },
				   static_cast<intptr_t>(centi));
}

void AppTask::StepTemperature(int16_t deltaCenti)
{
	PlatformMgr().ScheduleWork(
		[](intptr_t arg) {
			AppTask &app = Instance();
			app.ApplyTemperature(static_cast<int32_t>(app.mCurrentTemperature) + static_cast<int32_t>(arg));
		},
		static_cast<intptr_t>(deltaCenti));
}

void AppTask::ApplyTemperature(int32_t centi)
{
	/* 클러스터가 정한 범위(ZAP 의 Min/MaxMeasuredValue) 안으로 자른다. */
	if (centi < mTemperatureSensorMinValue) {
		centi = mTemperatureSensorMinValue;
	} else if (centi > mTemperatureSensorMaxValue) {
		centi = mTemperatureSensorMaxValue;
	}
	mCurrentTemperature = static_cast<int16_t>(centi);

	Protocols::InteractionModel::Status status =
		Clusters::TemperatureMeasurement::Attributes::MeasuredValue::Set(kTemperatureSensorEndpointId,
										  mCurrentTemperature);
	if (status != Protocols::InteractionModel::Status::Success) {
		LOG_ERR("Updating temperature measurement failed %x", to_underlying(status));
		return;
	}

	int32_t absolute = centi < 0 ? -centi : centi;
	LOG_INF("Virtual temperature %s%d.%02d C", centi < 0 ? "-" : "", absolute / 100, absolute % 100);
}

CHIP_ERROR AppTask::Init()
{
	/* Initialize Matter stack */
	ReturnErrorOnFailure(Nrf::Matter::PrepareServer());

	if (!Nrf::GetBoard().Init(ButtonEventHandler)) {
		LOG_ERR("User interface initialization failed.");
		return CHIP_ERROR_INCORRECT_STATE;
	}

	/* Register Matter event handler that controls the connectivity status LED based on the captured Matter network
	 * state. */
	ReturnErrorOnFailure(Nrf::Matter::RegisterEventHandler(Nrf::Board::DefaultMatterEventHandler, 0));

	ReturnErrorOnFailure(sIdentifyCluster.Init());
	ReturnErrorOnFailure(sLightIdentifyCluster.Init());
	ReturnErrorOnFailure(sTempIdentifyCluster.Init());
	ReturnErrorOnFailure(sOccupancyInstance.Init());
	SetSensing(true);

	ReturnErrorOnFailure(Nrf::Matter::StartServer());

	LOG_INF("Zone x[%d..%d] y[%d..%d] mm", kZone.xmin, kZone.xmax, kZone.ymin, kZone.ymax);
	if (BedRules::BedEnabled(kBedConfig.bed)) {
		LOG_INF("Bed x[%d..%d] y[%d..%d] split %d edge %d, follow %d ms", kBedConfig.bed.xmin,
			kBedConfig.bed.xmax, kBedConfig.bed.ymin, kBedConfig.bed.ymax, kBedConfig.bed.splitX,
			kBedConfig.bed.edgeMm, static_cast<int>(kBedConfig.followMs));
	} else {
		LOG_INF("Bed 미설정 → 예전 규칙 (구역 안 사람 있으면 occ 1)");
	}
#ifdef CONFIG_JAMJARI_DIRECT_UPLOAD
	/* 레이더보다 먼저: 사건이 들어오기 전에 보드 무작위 값·부팅번호를 정해 둔다 */
	DirectUpload::Init();
#endif
#ifdef CONFIG_JAMJARI_FUSION
	FusionReset();
	LOG_INF("fusion: 보드 추정 켜짐 (재생 빌드, 장면 시각)");
	if (Ld2450::Init(OnRadarFrame, OnRadarTick, OnReplayFrame) != 0) {
#else
	if (Ld2450::Init(OnRadarFrame, OnRadarTick) != 0) {
#endif
		/* 레이더가 없어도 Matter 기기로는 계속 동작한다 (Occupancy=0 유지) */
		LOG_ERR("LD2450 init failed");
	}

	return CHIP_NO_ERROR;
}

CHIP_ERROR AppTask::StartApp()
{
	ReturnErrorOnFailure(Init());

	/* 가상 온도 범위를 ZAP 값에서 다시 읽는다. 못 읽어도 레이더는 계속 돌아야 하니 기본값(-10~40도)으로 간다. */
	DataModel::Nullable<int16_t> val;
	PlatformMgr().LockChipStack();
	if (Clusters::TemperatureMeasurement::Attributes::MinMeasuredValue::Get(kTemperatureSensorEndpointId, val) ==
		    Protocols::InteractionModel::Status::Success &&
	    !val.IsNull()) {
		mTemperatureSensorMinValue = val.Value();
	} else {
		LOG_ERR("Failed to get temperature measurement min value");
	}
	if (Clusters::TemperatureMeasurement::Attributes::MaxMeasuredValue::Get(kTemperatureSensorEndpointId, val) ==
		    Protocols::InteractionModel::Status::Success &&
	    !val.IsNull()) {
		mTemperatureSensorMaxValue = val.Value();
	} else {
		LOG_ERR("Failed to get temperature measurement max value");
	}
	PlatformMgr().UnlockChipStack();

	/* 시작 값. 이후로는 버튼·셸 명령으로만 바뀐다. */
	SetTemperature(CONFIG_JAMJARI_TEMP_START_CENTI);

	while (true) {
		Nrf::DispatchNextTask();
	}

	return CHIP_NO_ERROR;
}
```

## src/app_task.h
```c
/*
 * Copyright (c) 2025 Nordic Semiconductor ASA
 *
 * SPDX-License-Identifier: LicenseRef-Nordic-5-Clause
 */

#pragma once

#include "board/board.h"

#include <platform/CHIPDeviceLayer.h>

struct Identify;

class AppTask {
public:
	static AppTask &Instance()
	{
		static AppTask sAppTask;
		return sAppTask;
	};

	CHIP_ERROR StartApp();

	/* 「감지 잠시 멈춤」 스위치(엔드포인트 2 On/Off). on=false 면 멈춤. Matter(CHIP) 스레드에서만 부른다. */
	static void SetSensing(bool on);

	/* 시연용 가상 온도(엔드포인트 3). 값은 모두 클러스터 단위(0.01 C). Matter 스레드 밖에서 불러도 된다(작업을 넘긴다). */
	void SetTemperature(int16_t centi);
	void StepTemperature(int16_t deltaCenti);

	int16_t GetCurrentTemperature() const { return mCurrentTemperature; }
	int16_t GetMinTemperature() const { return mTemperatureSensorMinValue; }
	int16_t GetMaxTemperature() const { return mTemperatureSensorMaxValue; }

private:
	CHIP_ERROR Init();

	/* Matter 스레드에서만 부른다. */
	void ApplyTemperature(int32_t centi);

	static void ButtonEventHandler(Nrf::ButtonState state, Nrf::ButtonMask hasChanged);

	/* ZAP 의 Min/MaxMeasuredValue 와 같은 값. StartApp 에서 다시 읽기 전(서버가 막 뜬 사이)에
	 * 버튼·셸이 들어와도 0..0 으로 잘리지 않게 미리 채워 둔다. */
	int16_t mTemperatureSensorMaxValue = 4000;
	int16_t mTemperatureSensorMinValue = -1000;
	int16_t mCurrentTemperature = 0;
};
```

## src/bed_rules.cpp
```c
/*
 * 침대 칸 규칙 구현. Zephyr 헤더를 쓰지 않는다 — 호스트(clang++)와 타깃 양쪽에서 컴파일된다.
 */

#include "bed_rules.h"

#include <cstdio>

namespace BedRules {
namespace {

constexpr int64_t kSize1Dist2 = 100 * 100; /* 움직인 거리 <10cm → size 1 (웹 기획 §10 임시값) */
constexpr int64_t kSize2Dist2 = 300 * 300; /* <30cm → 2, 그 이상 → 3 */
constexpr uint8_t kBitL = 1;
constexpr uint8_t kBitR = 2;

size_t Idx(Side s)
{
	return s == Side::kL ? 0 : 1;
}

SideTag TagOf(Side s)
{
	switch (s) {
	case Side::kL:
		return SideTag::kL;
	case Side::kR:
		return SideTag::kR;
	default:
		return SideTag::kNone;
	}
}

bool InBed(const Bed &bed, int32_t x, int32_t y)
{
	return bed.xmin <= x && x <= bed.xmax && bed.ymin <= y && y <= bed.ymax;
}

/* 가장자리 띠 = 좌우 두 변 + 발치(ymin, 레이더 쪽). 머리맡(ymax)은 띠 없음 — 베개 위 머리 움직임이
 * 사라져도 자리 뜸이 아니다(설계서 §6-2 H1). */
bool InEdge(const Bed &bed, int32_t x, int32_t y)
{
	return InBed(bed, x, y) &&
	       (x < bed.xmin + bed.edgeMm || x > bed.xmax - bed.edgeMm || y < bed.ymin + bed.edgeMm);
}

/* 이 점 말고 같은 칸을 켜 둔 다른 살아 있는 점이 있나 (한 사람이 점 2개로 보일 때, §6-2 H3) */
bool OtherOwner(const State &state, Side s, uint32_t nameIndex, const bool *alive)
{
	for (size_t m = 0; m < state.memoCount; m++) {
		const TrackMemo &other = state.memo[m];
		if (other.nameIndex != nameIndex && other.owner == s && (alive == nullptr || alive[m])) {
			return true;
		}
	}
	return false;
}

Side SideOf(const Bed &bed, int32_t x)
{
	return x < bed.splitX ? Side::kL : Side::kR;
}

int64_t Dist2(int32_t ax, int32_t ay, int32_t bx, int32_t by)
{
	int64_t dx = ax - bx;
	int64_t dy = ay - by;
	return dx * dx + dy * dy;
}

void Emit(State &state, EventBuf &out, Kind kind, int64_t startMs, int64_t endMs, uint8_t size, int32_t x,
	  int32_t y, uint8_t count, SideTag side)
{
	if (out.n >= EventBuf::kMax) {
		out.overflow++;
		return;
	}
	out.ev[out.n++] = { state.seq++, kind, startMs, endMs, size, x, y, count, side };
}

/* 칸 표시 켬. 꺼진 뒤 다시 켜지는 거면 away 한 줄. */
void SetSide(State &state, Side s, int64_t nowMs, int32_t x, int32_t y, EventBuf &out)
{
	size_t i = Idx(s);
	if (state.hold[i]) {
		return;
	}
	state.hold[i] = true;
	state.lastSetSide = s;
	state.lastSetX = x;
	state.lastSetY = y;
	if (state.awayPending[i]) {
		state.awayPending[i] = false;
		Emit(state, out, Kind::kAway, state.awayStartMs[i], nowMs, 0, state.awayX[i], state.awayY[i], 1,
		     TagOf(s));
	}
}

/* 그 칸 표시만 끈다(away 없음). 그 칸을 켜 둔 점들의 주인 표시도 지운다. */
void DropSide(State &state, Side s)
{
	state.hold[Idx(s)] = false;
	for (size_t m = 0; m < state.memoCount; m++) {
		if (state.memo[m].owner == s) {
			state.memo[m].owner = Side::kNone;
		}
	}
}

/* 자리 뜸: 칸 표시 끄고, 돌아오면 away 를 낼 수 있게 나간 시각·자리를 기억한다. */
void LeaveSide(State &state, Side s, int64_t atMs, int32_t x, int32_t y)
{
	size_t i = Idx(s);
	if (!state.hold[i]) {
		return;
	}
	DropSide(state, s);
	state.awayPending[i] = true;
	state.awayStartMs[i] = atMs;
	state.awayX[i] = x;
	state.awayY[i] = y;
	state.lastClearTag = TagOf(s);
	state.lastClearX = x;
	state.lastClearY = y;
}

uint8_t SizeOf(int64_t dist2)
{
	if (dist2 < kSize1Dist2) {
		return 1;
	}
	return dist2 < kSize2Dist2 ? 2 : 3;
}

void EmitGroup(State &state, const Config &cfg, EventBuf &out)
{
	Group &g = state.group;
	SideTag tag;
	if (g.sides == (kBitL | kBitR)) {
		tag = SideTag::kLR;
	} else {
		tag = g.sides == kBitL ? SideTag::kL : SideTag::kR;
		/* LR 앞뒤로는 이어짐을 붙이지 않는다. 겹치지 않으므로 간격은 항상 0보다 크다. */
		bool prevSingleOther = state.prevEmitted && state.prevSides != (kBitL | kBitR) &&
				       state.prevSides != g.sides;
		if (prevSingleOther && g.startMs - state.prevEndMs <= cfg.followMs) {
			tag = g.sides == kBitR ? SideTag::kLthenR : SideTag::kRthenL;
		}
	}
	Emit(state, out, Kind::kMove, g.startMs, g.endMs, SizeOf(g.maxDist2), g.x0, g.y0,
	     static_cast<uint8_t>(g.countL + g.countR), tag);
	state.prevEmitted = true;
	state.prevSides = g.sides;
	state.prevEndMs = g.endMs;
	g.pending = false;
}

/* 닫힌 칸 움직임을 묶음에 넣는다. 시간이 겹치면 합치고, 아니면 앞 묶음을 먼저 낸다. */
void AddToGroup(State &state, const Config &cfg, const Episode &ep, size_t i, EventBuf &out)
{
	Group &g = state.group;
	uint8_t bit = i == 0 ? kBitL : kBitR;
	/* 묶음이 반대 칸의 진행 중 움직임을 기다리는 중이면, 그 움직임도 묶음에 들어갈 것이므로 겹침 비교 구간을
	 * 그 움직임의 지금까지 끝으로 넓힌다(긴 L 도중 R 이 두 번 → 한 줄 LR, §6-2 M1). */
	int64_t groupEnd = g.endMs;
	const Episode &other = state.ep[1 - i];
	if (g.pending && other.active && other.startMs <= g.endMs && other.lastMs > groupEnd) {
		groupEnd = other.lastMs;
	}
	if (g.pending && ep.startMs <= groupEnd && g.startMs <= ep.lastMs) {
		if (ep.startMs < g.startMs) {
			g.startMs = ep.startMs;
			g.x0 = ep.x0;
			g.y0 = ep.y0;
		}
		if (ep.lastMs > g.endMs) {
			g.endMs = ep.lastMs;
		}
		g.sides |= bit;
		if (ep.maxDist2 > g.maxDist2) {
			g.maxDist2 = ep.maxDist2;
		}
	} else {
		if (g.pending) {
			EmitGroup(state, cfg, out);
		}
		g = { true, ep.startMs, ep.lastMs, bit, ep.x0, ep.y0, ep.maxDist2, 0, 0 };
	}
	uint8_t &count = i == 0 ? g.countL : g.countR;
	if (ep.maxCount > count) {
		count = ep.maxCount;
	}
}

/* 끊긴 지 gap 넘은 칸 움직임을 닫고, 더 겹칠 게 없는 묶음을 낸다. */
void CloseAndFlush(State &state, const Config &cfg, int64_t nowMs, EventBuf &out)
{
	for (size_t i = 0; i < 2; i++) {
		Episode &ep = state.ep[i];
		if (ep.active && nowMs - ep.lastMs > cfg.moveGapMs) {
			ep.active = false;
			if (ep.lastMs - ep.startMs >= cfg.moveMinMs) {
				AddToGroup(state, cfg, ep, i, out);
			}
		}
	}
	if (!state.group.pending) {
		return;
	}
	for (const Episode &ep : state.ep) {
		/* 진행 중인 움직임이 묶음과 겹치면 끝날 때까지 기다린다(짧아서 버려지면 그때 낸다) */
		if (ep.active && ep.startMs <= state.group.endMs) {
			return;
		}
	}
	EmitGroup(state, cfg, out);
}

void SafetyAndOcc(State &state, const Config &cfg, int64_t nowMs, EventBuf &out)
{
	bool any = state.hold[0] || state.hold[1];
	if (any && nowMs - state.lastInBedMs >= cfg.holdMaxMs) {
		/* 안전장치: 나가는 걸 놓쳤다고 본다. away 는 내지 않는다. off 줄은 켜져 있던 칸(둘 다면 LR)과
		 * 침대 안 마지막 자리. */
		state.lastClearTag = state.hold[0] && state.hold[1] ? SideTag::kLR
				     : state.hold[0]		    ? SideTag::kL
								    : SideTag::kR;
		state.lastClearX = state.lastInBedX;
		state.lastClearY = state.lastInBedY;
		DropSide(state, Side::kL);
		DropSide(state, Side::kR);
		any = false;
	}

	if (any) {
		state.allClearSinceMs = -1;
		if (!state.occupied) {
			state.occupied = true;
			Emit(state, out, Kind::kOn, nowMs, nowMs, 0, state.lastSetX, state.lastSetY, 1,
			     TagOf(state.lastSetSide));
		}
		return;
	}
	if (state.allClearSinceMs < 0) {
		state.allClearSinceMs = nowMs;
	}
	if (state.occupied && nowMs - state.allClearSinceMs >= cfg.leaveDelayMs) {
		state.occupied = false;
		Emit(state, out, Kind::kOff, nowMs, nowMs, 0, state.lastClearX, state.lastClearY, 0,
		     state.lastClearTag);
	}
}

/* 침대 좌표 미설정: 예전 규칙. 트랙이 있으면 시계를 다시 재고, 마지막으로 있던 때부터 leaveDelayMs 지나면 0 */
void LegacyOcc(State &state, const Config &cfg, size_t trackCount, int32_t x, int32_t y, int64_t nowMs,
	       EventBuf &out)
{
	if (trackCount > 0) {
		state.lastLiveMs = nowMs;
		state.lastClearX = x;
		state.lastClearY = y;
		if (!state.occupied) {
			state.occupied = true;
			Emit(state, out, Kind::kOn, nowMs, nowMs, 0, x, y, static_cast<uint8_t>(trackCount),
			     SideTag::kNone);
		}
		return;
	}
	if (state.occupied && nowMs - state.lastLiveMs >= cfg.leaveDelayMs) {
		state.occupied = false;
		Emit(state, out, Kind::kOff, nowMs, nowMs, 0, state.lastClearX, state.lastClearY, 0, SideTag::kNone);
	}
}

} /* namespace */

bool BedEnabled(const Bed &bed)
{
	return bed.xmin != 0 || bed.xmax != 0 || bed.ymin != 0 || bed.ymax != 0;
}

bool Update(State &state, const Config &cfg, const Tracker::State &tracker, int64_t nowMs, EventBuf &out)
{
	const Bed &bed = cfg.bed;
	if (!BedEnabled(bed)) {
		int32_t x = tracker.count ? tracker.tracks[0].x : 0;
		int32_t y = tracker.count ? tracker.tracks[0].y : 0;
		LegacyOcc(state, cfg, tracker.count, x, y, nowMs, out);
		return state.occupied;
	}

	/* 1. 시간으로 닫히는 움직임 먼저 (새 점이 gap 뒤에 오면 다른 건) */
	CloseAndFlush(state, cfg, nowMs, out);

	/* 2. 트래커에서 지워진 점: 가장자리 띠에서 사라졌으면 자리 뜸
	 *    (단 같은 칸을 켜 둔 다른 살아 있는 점이 있으면 안 끔) */
	bool alive[Tracker::kMaxTracks] = {};
	for (size_t m = 0; m < state.memoCount; m++) {
		for (size_t t = 0; t < tracker.count; t++) {
			if (tracker.tracks[t].nameIndex == state.memo[m].nameIndex) {
				alive[m] = true;
				break;
			}
		}
	}
	for (size_t m = 0; m < state.memoCount; m++) {
		const TrackMemo &memo = state.memo[m];
		if (!alive[m] && memo.owner != Side::kNone && InEdge(bed, memo.x, memo.y) &&
		    !OtherOwner(state, memo.owner, memo.nameIndex, alive)) {
			LeaveSide(state, memo.owner, memo.lastSeenMs, memo.x, memo.y);
		}
	}
	size_t kept = 0;
	for (size_t m = 0; m < state.memoCount; m++) {
		if (alive[m]) {
			state.memo[kept++] = state.memo[m];
		}
	}
	state.memoCount = kept;

	/* 3. 이번 프레임에 잡힌 점 */
	uint8_t sideCount[2] = {};
	int32_t sideX[2][Tracker::kMaxTracks];
	int32_t sideY[2][Tracker::kMaxTracks];
	for (size_t t = 0; t < tracker.count; t++) {
		const Tracker::Track &tr = tracker.tracks[t];
		TrackMemo *memo = nullptr;
		for (size_t m = 0; m < state.memoCount; m++) {
			if (state.memo[m].nameIndex == tr.nameIndex) {
				memo = &state.memo[m];
				break;
			}
		}
		if (memo == nullptr) {
			if (state.memoCount >= Tracker::kMaxTracks) {
				continue;
			}
			memo = &state.memo[state.memoCount++];
			*memo = { tr.nameIndex, Side::kNone, tr.x, tr.y, nowMs };
		}
		if (!tr.seen) {
			continue;
		}
		memo->x = tr.x;
		memo->y = tr.y;
		memo->lastSeenMs = nowMs;

		if (InBed(bed, tr.x, tr.y)) {
			state.lastInBedMs = nowMs;
			state.lastInBedX = tr.x;
			state.lastInBedY = tr.y;
			Side s = SideOf(bed, tr.x);
			if (memo->owner == Side::kNone) {
				memo->owner = s;
			} else if (memo->owner != s && !state.hold[Idx(s)]) {
				/* 같은 점이 빈 반대 칸으로 넘어감 → 표시를 넘긴다. 넘어간 칸이 이미 켜져 있으면(옆사람)
				 * 넘기지 않고 이 점을 원래 칸 사람으로 계속 본다(§6-2 H2). */
				DropSide(state, memo->owner);
				memo->owner = s;
			}
			SetSide(state, s, nowMs, tr.x, tr.y, out);
			size_t i = Idx(s);
			sideX[i][sideCount[i]] = tr.x;
			sideY[i][sideCount[i]] = tr.y;
			sideCount[i]++;
		} else if (memo->owner != Side::kNone) {
			/* 그 칸에서 온 점이 침대 밖에서 보임 → 자리 뜸 (같은 칸에 다른 점이 남아 있으면 이 점만 놓음) */
			if (OtherOwner(state, memo->owner, memo->nameIndex, nullptr)) {
				memo->owner = Side::kNone;
			} else {
				LeaveSide(state, memo->owner, nowMs, tr.x, tr.y);
			}
		}
	}

	/* 4. 칸별 움직임 */
	for (size_t i = 0; i < 2; i++) {
		if (sideCount[i] == 0) {
			continue;
		}
		Episode &ep = state.ep[i];
		if (!ep.active) {
			ep = { true, nowMs, nowMs, sideX[i][0], sideY[i][0], 0, 0 };
		}
		ep.lastMs = nowMs;
		if (sideCount[i] > ep.maxCount) {
			ep.maxCount = sideCount[i];
		}
		for (size_t k = 0; k < sideCount[i]; k++) {
			int64_t d2 = Dist2(sideX[i][k], sideY[i][k], ep.x0, ep.y0);
			if (d2 > ep.maxDist2) {
				ep.maxDist2 = d2;
			}
		}
	}

	/* 5. 안전장치·occ (묶음 내보내기는 다음 프레임·틱의 1단계에서) */
	SafetyAndOcc(state, cfg, nowMs, out);
	return state.occupied;
}

bool Tick(State &state, const Config &cfg, int64_t nowMs, EventBuf &out)
{
	if (!BedEnabled(cfg.bed)) {
		LegacyOcc(state, cfg, 0, 0, 0, nowMs, out);
		return state.occupied;
	}
	CloseAndFlush(state, cfg, nowMs, out);
	SafetyAndOcc(state, cfg, nowMs, out);
	return state.occupied;
}

int FormatEvent(const Event &ev, char *buf, size_t len)
{
	static const char *const kKinds[] = { "on", "off", "move", "away", "seat", "spot" };
	static const char *const kSides[] = { "", "L", "R", "LR", "L>R", "R>L" };
	return snprintf(buf, len, "JJ1,EV,%lu,%s,%lld,%lld,%u,%ld,%ld,%u,,%s", static_cast<unsigned long>(ev.seq),
			kKinds[static_cast<size_t>(ev.kind)], static_cast<long long>(ev.startMs),
			static_cast<long long>(ev.endMs), static_cast<unsigned>(ev.size), static_cast<long>(ev.x),
			static_cast<long>(ev.y), static_cast<unsigned>(ev.count),
			kSides[static_cast<size_t>(ev.side)]);
}

} /* namespace BedRules */
```
